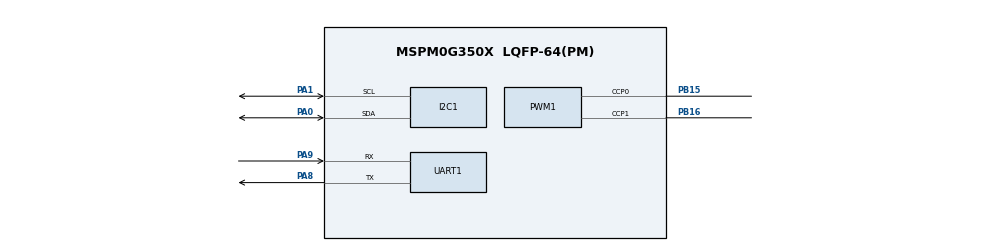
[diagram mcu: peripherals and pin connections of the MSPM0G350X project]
/**
 * @cliArgs --device "MSPM0G350X" --part "Default" --package "LQFP-64(PM)" --product "mspm0_sdk@2.05.00.05"
 * @versions {"tool":"1.27.1+4634"}
 */

/**
 * Import the modules used in this configuration.
 */
const GPIO   = scripting.addModule("/ti/driverlib/GPIO", {}, false);
const GPIO1  = GPIO.addInstance();
const GPIO2  = GPIO.addInstance();
const GPIO3  = GPIO.addInstance();
const GPIO4  = GPIO.addInstance();
const I2C    = scripting.addModule("/ti/driverlib/I2C", {}, false);
const I2C1   = I2C.addInstance();
const PWM    = scripting.addModule("/ti/driverlib/PWM", {}, false);
const PWM1   = PWM.addInstance();
const SYSCTL = scripting.addModule("/ti/driverlib/SYSCTL");
const TIMER  = scripting.addModule("/ti/driverlib/TIMER", {}, false);
const TIMER1 = TIMER.addInstance();
const TIMER2 = TIMER.addInstance();
const UART   = scripting.addModule("/ti/driverlib/UART", {}, false);
const UART1  = UART.addInstance();

/**
 * Write custom configuration values to the imported modules.
 */
GPIO1.$name                          = "MOTOR_GPIO";
GPIO1.associatedPins.create(5);
GPIO1.associatedPins[0].assignedPort = "PORTB";
GPIO1.associatedPins[0].$name        = "AIN1";
GPIO1.associatedPins[0].assignedPin  = "18";
GPIO1.associatedPins[1].$name        = "AIN2";
GPIO1.associatedPins[1].assignedPort = "PORTB";
GPIO1.associatedPins[1].assignedPin  = "24";
GPIO1.associatedPins[2].$name        = "BIN1";
GPIO1.associatedPins[2].assignedPort = "PORTA";
GPIO1.associatedPins[2].assignedPin  = "22";
GPIO1.associatedPins[3].$name        = "BIN2";
GPIO1.associatedPins[3].assignedPort = "PORTB";
GPIO1.associatedPins[3].assignedPin  = "19";
GPIO1.associatedPins[4].$name        = "STBY";
GPIO1.associatedPins[4].assignedPort = "PORTA";
GPIO1.associatedPins[4].assignedPin  = "26";

const Board = scripting.addModule("/ti/driverlib/Board", {}, false);

GPIO2.$name                          = "ENCODER_GPIO";
GPIO2.associatedPins.create(4);
GPIO2.associatedPins[0].$name        = "ENC1_A";
GPIO2.associatedPins[0].direction    = "INPUT";
GPIO2.associatedPins[0].assignedPort = "PORTA";
GPIO2.associatedPins[0].assignedPin  = "31";
GPIO2.associatedPins[0].interruptEn  = true;
GPIO2.associatedPins[0].polarity     = "RISE";
GPIO2.associatedPins[1].$name        = "ENC1_B";
GPIO2.associatedPins[1].direction    = "INPUT";
GPIO2.associatedPins[1].assignedPort = "PORTB";
GPIO2.associatedPins[1].assignedPin  = "20";
GPIO2.associatedPins[2].$name        = "ENC2_A";
GPIO2.associatedPins[2].direction    = "INPUT";
GPIO2.associatedPins[2].assignedPort = "PORTB";
GPIO2.associatedPins[2].assignedPin  = "13";
GPIO2.associatedPins[2].interruptEn  = true;
GPIO2.associatedPins[2].polarity     = "RISE";
GPIO2.associatedPins[3].$name        = "ENC2_B";
GPIO2.associatedPins[3].direction    = "INPUT";
GPIO2.associatedPins[3].assignedPort = "PORTA";
GPIO2.associatedPins[3].assignedPin  = "10";

GPIO3.$name                          = "ALERT_GPIO";
GPIO3.associatedPins.create(6);
GPIO3.associatedPins[0].$name        = "BUZZER";
GPIO3.associatedPins[0].assignedPort = "PORTB";
GPIO3.associatedPins[0].assignedPin  = "0";
GPIO3.associatedPins[1].$name        = "LED_TASK";
GPIO3.associatedPins[1].assignedPort = "PORTA";
GPIO3.associatedPins[1].assignedPin  = "17";
GPIO3.associatedPins[2].$name        = "LED1";
GPIO3.associatedPins[2].assignedPort = "PORTB";
GPIO3.associatedPins[2].assignedPin  = "9";
GPIO3.associatedPins[3].$name        = "LED2";
GPIO3.associatedPins[3].assignedPort = "PORTB";
GPIO3.associatedPins[3].assignedPin  = "2";
GPIO3.associatedPins[4].$name        = "LED3";
GPIO3.associatedPins[4].assignedPort = "PORTB";
GPIO3.associatedPins[4].assignedPin  = "3";
GPIO3.associatedPins[5].$name        = "LED4";
GPIO3.associatedPins[5].assignedPort = "PORTA";
GPIO3.associatedPins[5].assignedPin  = "24";

GPIO4.$name                              = "KEY_GPIO";
GPIO4.associatedPins.create(2);
GPIO4.associatedPins[0].$name            = "KEY_MODE";
GPIO4.associatedPins[0].direction        = "INPUT";
GPIO4.associatedPins[0].assignedPort     = "PORTB";
GPIO4.associatedPins[0].assignedPin      = "21";
GPIO4.associatedPins[0].internalResistor = "PULL_UP";
GPIO4.associatedPins[1].$name            = "KEY_START";
GPIO4.associatedPins[1].direction        = "INPUT";
GPIO4.associatedPins[1].assignedPort     = "PORTA";
GPIO4.associatedPins[1].assignedPin      = "12";
GPIO4.associatedPins[1].internalResistor = "PULL_UP";

I2C1.$name                     = "I2C_0";
I2C1.basicEnableController     = true;
I2C1.peripheral.$assign        = "I2C0";
I2C1.peripheral.sdaPin.$assign = "PA0";
I2C1.peripheral.sclPin.$assign = "PA1";
I2C1.sdaPinConfig.$name        = "ti_driverlib_gpio_GPIOPinGeneric0";
I2C1.sclPinConfig.$name        = "ti_driverlib_gpio_GPIOPinGeneric1";

PWM1.timerCount                         = 3200;
PWM1.$name                              = "MOTOR_PWM";
PWM1.peripheral.$assign                 = "TIMG8";
PWM1.peripheral.ccp0Pin.$assign         = "PB15";
PWM1.peripheral.ccp1Pin.$assign         = "PB16";
PWM1.PWM_CHANNEL_0.$name                = "ti_driverlib_pwm_PWMTimerCC0";
PWM1.PWM_CHANNEL_1.$name                = "ti_driverlib_pwm_PWMTimerCC1";
PWM1.ccp0PinConfig.$name                = "ti_driverlib_gpio_GPIOPinGeneric2";
PWM1.ccp0PinConfig.direction            = scripting.forceWrite("OUTPUT");
PWM1.ccp0PinConfig.hideOutputInversion  = scripting.forceWrite(false);
PWM1.ccp0PinConfig.onlyInternalResistor = scripting.forceWrite(false);
PWM1.ccp0PinConfig.passedPeripheralType = scripting.forceWrite("Digital");
PWM1.ccp1PinConfig.$name                = "ti_driverlib_gpio_GPIOPinGeneric3";
PWM1.ccp1PinConfig.direction            = scripting.forceWrite("OUTPUT");
PWM1.ccp1PinConfig.hideOutputInversion  = scripting.forceWrite(false);
PWM1.ccp1PinConfig.onlyInternalResistor = scripting.forceWrite(false);
PWM1.ccp1PinConfig.passedPeripheralType = scripting.forceWrite("Digital");

SYSCTL.forceDefaultClkConfig = true;
SYSCTL.powerSysInterrupts    = ["FLASH_SEC"];

TIMER1.$name = "TIMER_0";

TIMER2.$name = "TIMER_1";

UART1.$name                            = "GYRO_UART";
UART1.targetBaudRate                   = 115200;
UART1.peripheral.$assign               = "UART1";
UART1.peripheral.rxPin.$assign         = "PA9";
UART1.peripheral.txPin.$assign         = "PA8";
UART1.txPinConfig.$name                = "ti_driverlib_gpio_GPIOPinGeneric4";
UART1.txPinConfig.direction            = scripting.forceWrite("OUTPUT");
UART1.txPinConfig.hideOutputInversion  = scripting.forceWrite(false);
UART1.txPinConfig.onlyInternalResistor = scripting.forceWrite(false);
UART1.txPinConfig.passedPeripheralType = scripting.forceWrite("Digital");
UART1.rxPinConfig.$name                = "ti_driverlib_gpio_GPIOPinGeneric5";
UART1.rxPinConfig.hideOutputInversion  = scripting.forceWrite(false);
UART1.rxPinConfig.onlyInternalResistor = scripting.forceWrite(false);
UART1.rxPinConfig.passedPeripheralType = scripting.forceWrite("Digital");

/**
 * Pinmux solution for unlocked pins/peripherals. This ensures that minor changes to the automatic solver in a future
 * version of the tool will not impact the pinmux you originally saw.  These lines can be completely deleted in order to
 * re-solve from scratch.
 */
GPIO1.associatedPins[0].pin.$suggestSolution = "PB18";
GPIO1.associatedPins[1].pin.$suggestSolution = "PB24";
GPIO1.associatedPins[2].pin.$suggestSolution = "PA22";
GPIO1.associatedPins[3].pin.$suggestSolution = "PB19";
GPIO1.associatedPins[4].pin.$suggestSolution = "PA26";
Board.peripheral.$suggestSolution            = "DEBUGSS";
Board.peripheral.swclkPin.$suggestSolution   = "PA20";
Board.peripheral.swdioPin.$suggestSolution   = "PA19";
GPIO2.associatedPins[0].pin.$suggestSolution = "PA31";
GPIO2.associatedPins[1].pin.$suggestSolution = "PB20";
GPIO2.associatedPins[2].pin.$suggestSolution = "PB13";
GPIO2.associatedPins[3].pin.$suggestSolution = "PA10";
GPIO3.associatedPins[0].pin.$suggestSolution = "PB0";
GPIO3.associatedPins[1].pin.$suggestSolution = "PA17";
GPIO3.associatedPins[2].pin.$suggestSolution = "PB9";
GPIO3.associatedPins[3].pin.$suggestSolution = "PB2";
GPIO3.associatedPins[4].pin.$suggestSolution = "PB3";
GPIO3.associatedPins[5].pin.$suggestSolution = "PA24";
GPIO4.associatedPins[0].pin.$suggestSolution = "PB21";
GPIO4.associatedPins[1].pin.$suggestSolution = "PA12";
SYSCTL.peripheral.$suggestSolution           = "SYSCTL";
TIMER1.peripheral.$suggestSolution           = "TIMA1";
TIMER2.peripheral.$suggestSolution           = "TIMA0";
